# STM32F413xx register map
File version: 1.0
Registers are 32-bit, access not given, reset 0x0 unless marked. A register's access mark holds for its fields unless they carry their own. Offsets are from the block's base; [hi:lo] are bit positions; {n}, {i} and the like mark numbered series; 'fields as' and 'values as' point back to an identical list.

## SYSCFG
Base 0x40013800
0x00 MEMRMP
  [1:0] MEM_MODE
0x04 PMC
  [16] ADC1DC2
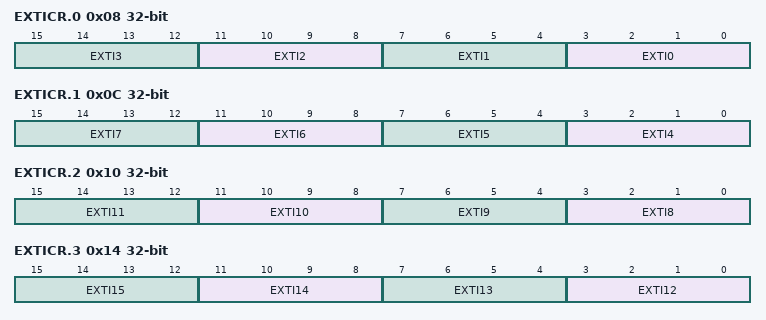
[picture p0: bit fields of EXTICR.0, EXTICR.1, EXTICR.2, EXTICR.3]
0x08 EXTICR.0
  [4n+3:4n] EXTI{n} (n=0..3)
0x0C EXTICR.1
  [4n-13:4n-16] EXTI{n} (n=4..7)
0x10 EXTICR.2
  [4n-29:4n-32] EXTI{n} (n=8..11)
0x14 EXTICR.3
  [4n-45:4n-48] EXTI{n} (n=12..15)
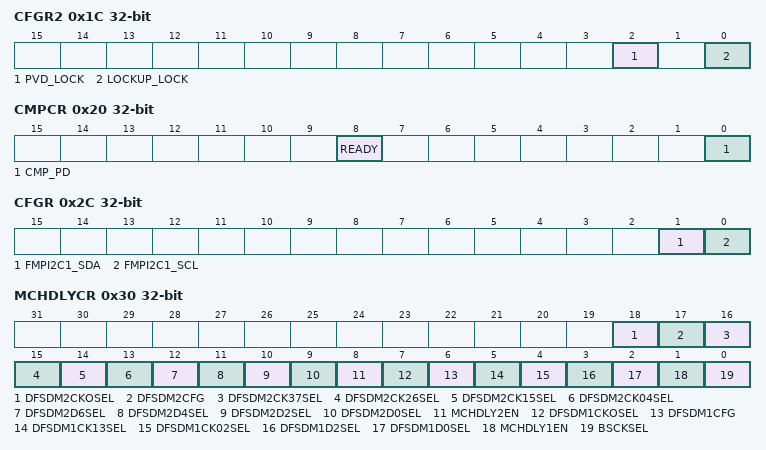
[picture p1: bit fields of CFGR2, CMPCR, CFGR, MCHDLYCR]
0x1C CFGR2
  [2] PVD_LOCK, [0] LOCKUP_LOCK
0x20 CMPCR
  [8] READY, [0] CMP_PD
0x2C CFGR
  [1] FMPI2C1_SDA, [0] FMPI2C1_SCL
0x30 MCHDLYCR
  [18] DFSDM2CKOSEL, [17] DFSDM2CFG, [16] DFSDM2CK37SEL, [15] DFSDM2CK26SEL, [14] DFSDM2CK15SEL, [13] DFSDM2CK04SEL, [12] DFSDM2D6SEL, [11] DFSDM2D4SEL, [10] DFSDM2D2SEL, [9] DFSDM2D0SEL, [8] MCHDLY2EN, [7] DFSDM1CKOSEL, [6] DFSDM1CFG, [5] DFSDM1CK13SEL, [4] DFSDM1CK02SEL, [3] DFSDM1D2SEL, [2] DFSDM1D0SEL, [1] MCHDLY1EN, [0] BSCKSEL

## EXTI
Base 0x40013C00
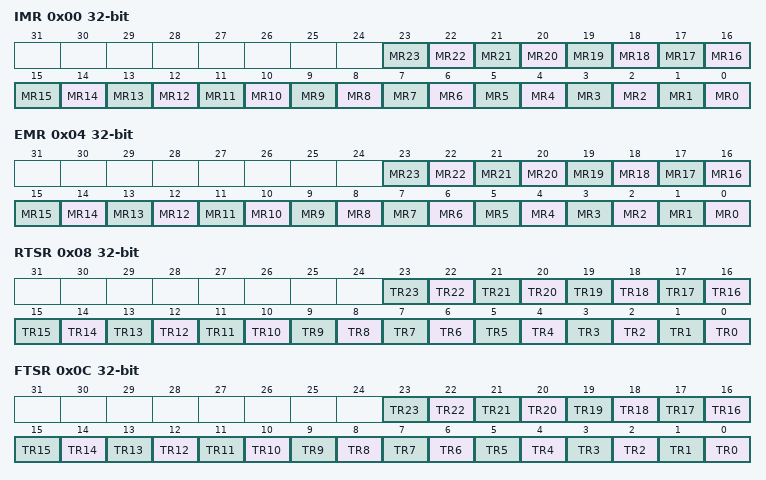
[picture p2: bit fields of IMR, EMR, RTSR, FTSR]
0x00 IMR
  [n] MR{n} (n=0..23)
0x04 EMR
  [n] MR{n} (n=0..23)
0x08 RTSR
  [n] TR{n} (n=0..23)
0x0C FTSR
  [n] TR{n} (n=0..23)
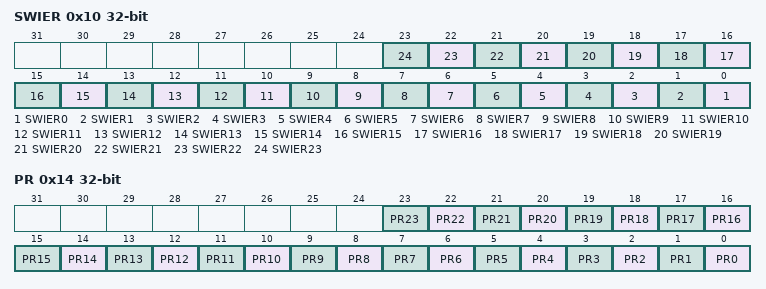
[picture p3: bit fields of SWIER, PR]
0x10 SWIER
  [n] SWIER{n} (n=0..23)
0x14 PR
  [n] PR{n} (n=0..23)

## SAI1
Base 0x40015800
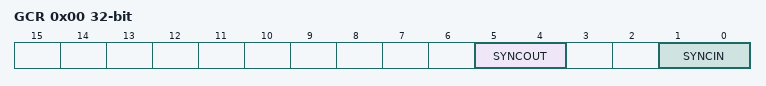
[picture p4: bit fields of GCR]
0x00 GCR
  [5:4] SYNCOUT, [1:0] SYNCIN
0x04 CR1A
0x08 CR2A
0x10 FRCRA
0x1C SLOTRA
0x24 CR1B
0x28 CR2B
0x2C IMRA
0x30 FRCRB
0x3C SLOTRB
0x40 SRA
0x4C IMRB
0x58 CLRFRA
0x60 SRB
0x74 DRA
0x78 CLRFRB
0x94 DRB

## DFSDM1
Base 0x40016000
Same registers: DFSDM2 0x40016400
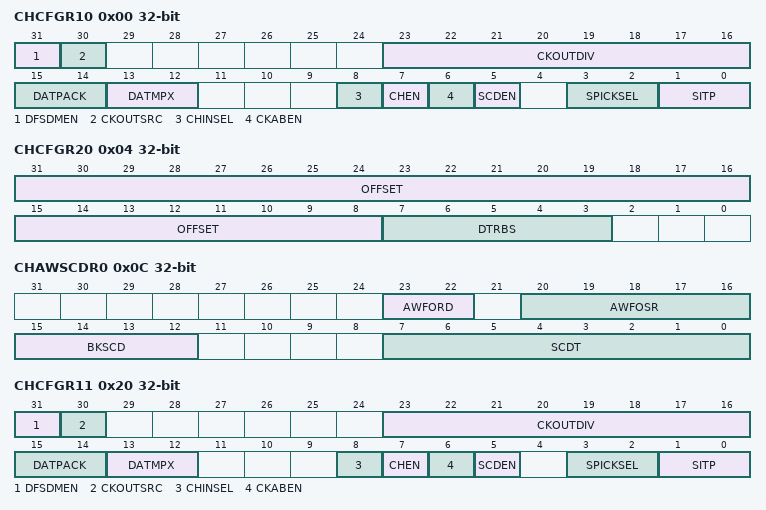
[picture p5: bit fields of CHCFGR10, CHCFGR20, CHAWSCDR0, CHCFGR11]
0x00 CHCFGR10
  [31] DFSDMEN, [30] CKOUTSRC, [23:16] CKOUTDIV, [15:14] DATPACK, [13:12] DATMPX, [8] CHINSEL, [7] CHEN, [6] CKABEN, [5] SCDEN, [3:2] SPICKSEL, [1:0] SITP
0x04 CHCFGR20
  [31:8] OFFSET, [7:3] DTRBS
0x0C CHAWSCDR0
  [23:22] AWFORD, [20:16] AWFOSR, [15:12] BKSCD, [7:0] SCDT
0x18 CHWDATAR0
0x20 CHCFGR11
  fields as CHCFGR10
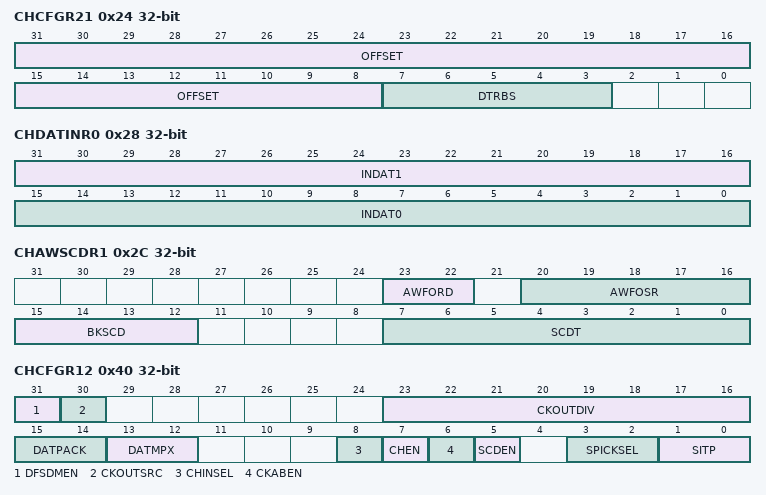
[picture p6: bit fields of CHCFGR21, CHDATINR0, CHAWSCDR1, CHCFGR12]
0x24 CHCFGR21
  [31:8] OFFSET, [7:3] DTRBS
0x28 CHDATINR0
  [31:16] INDAT1, [15:0] INDAT0
0x2C CHAWSCDR1
  [23:22] AWFORD, [20:16] AWFOSR, [15:12] BKSCD, [7:0] SCDT
0x38 CHWDATAR1
0x40 CHCFGR12
  fields as CHCFGR10
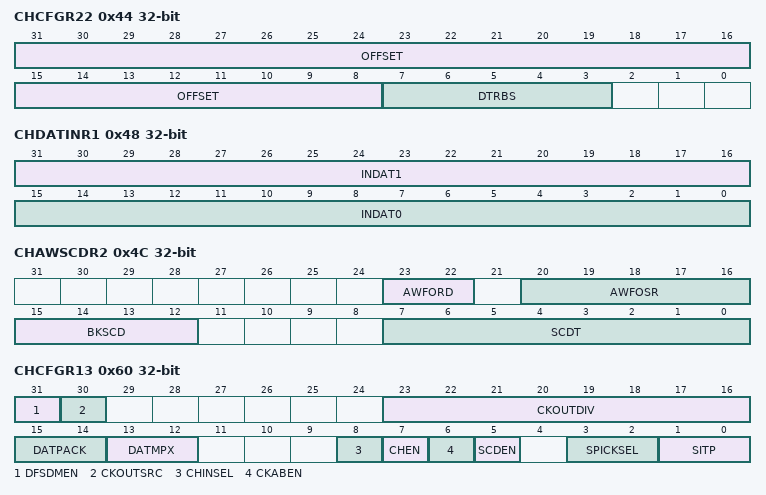
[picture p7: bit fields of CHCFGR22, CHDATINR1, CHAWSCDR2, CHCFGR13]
0x44 CHCFGR22
  [31:8] OFFSET, [7:3] DTRBS
0x48 CHDATINR1
  [31:16] INDAT1, [15:0] INDAT0
0x4C CHAWSCDR2
  [23:22] AWFORD, [20:16] AWFOSR, [15:12] BKSCD, [7:0] SCDT
0x58 CHWDATAR2
0x60 CHCFGR13
  fields as CHCFGR10
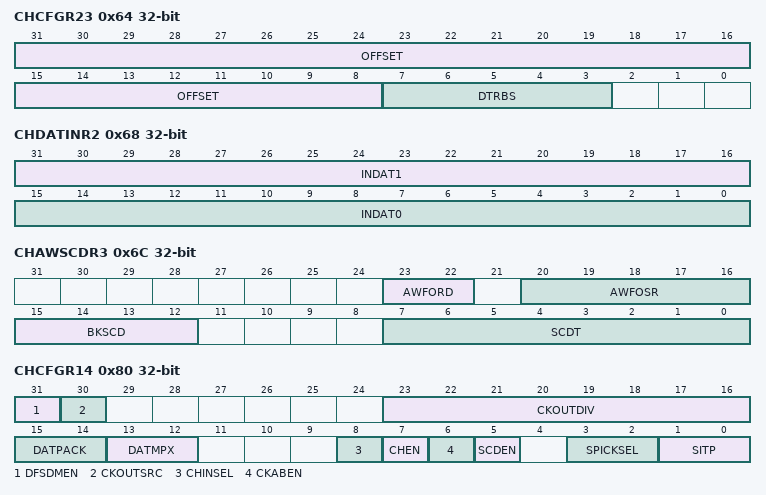
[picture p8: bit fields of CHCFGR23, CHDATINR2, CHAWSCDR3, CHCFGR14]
0x64 CHCFGR23
  [31:8] OFFSET, [7:3] DTRBS
0x68 CHDATINR2
  [31:16] INDAT1, [15:0] INDAT0
0x6C CHAWSCDR3
  [23:22] AWFORD, [20:16] AWFOSR, [15:12] BKSCD, [7:0] SCDT
0x78 CHWDATAR3
0x80 CHCFGR14
  fields as CHCFGR10
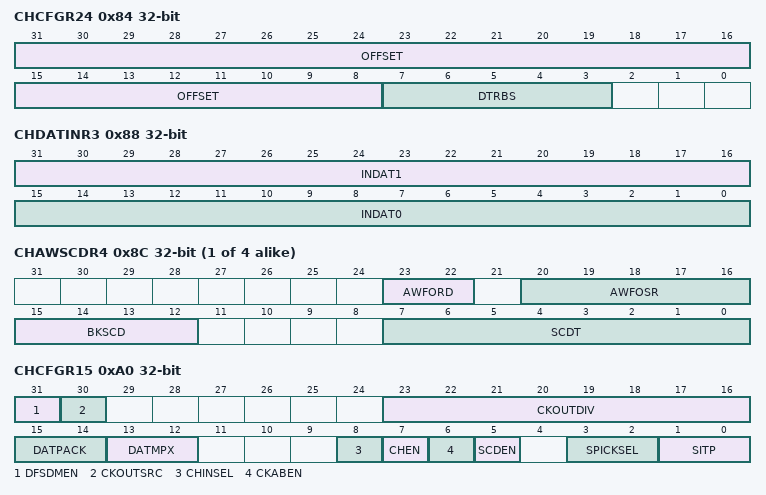
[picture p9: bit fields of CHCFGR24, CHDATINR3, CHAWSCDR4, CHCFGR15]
0x84 CHCFGR24
  [31:8] OFFSET, [7:3] DTRBS
0x88 CHDATINR3
  [31:16] INDAT1, [15:0] INDAT0
{0xC+0x20*i} CHAWSCDR{i} (i=4..7)
  [23:22] AWFORD, [20:16] AWFOSR, [15:12] BKSCD, [7:0] SCDT
{0x18+0x20*i} CHWDATAR{i} (i=4..7)
0xA0 CHCFGR15
  fields as CHCFGR10
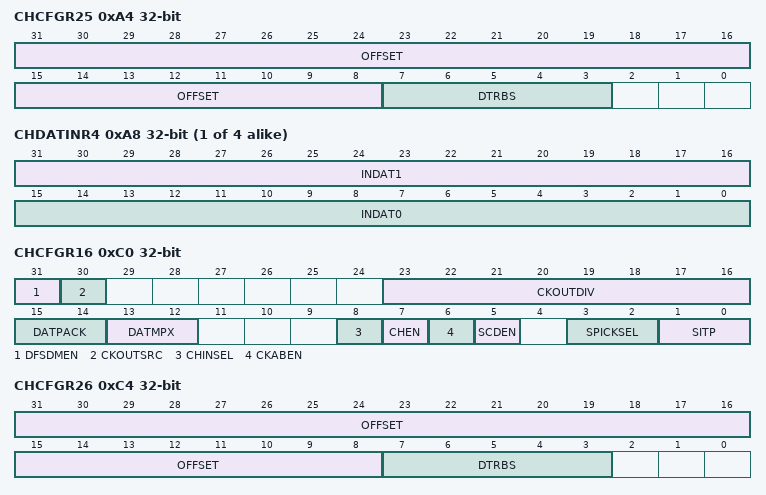
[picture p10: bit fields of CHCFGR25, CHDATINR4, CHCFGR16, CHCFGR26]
0xA4 CHCFGR25
  [31:8] OFFSET, [7:3] DTRBS
{0x28+0x20*i} CHDATINR{i} (i=4..7)
  [31:16] INDAT1, [15:0] INDAT0
0xC0 CHCFGR16
  fields as CHCFGR10
0xC4 CHCFGR26
  [31:8] OFFSET, [7:3] DTRBS
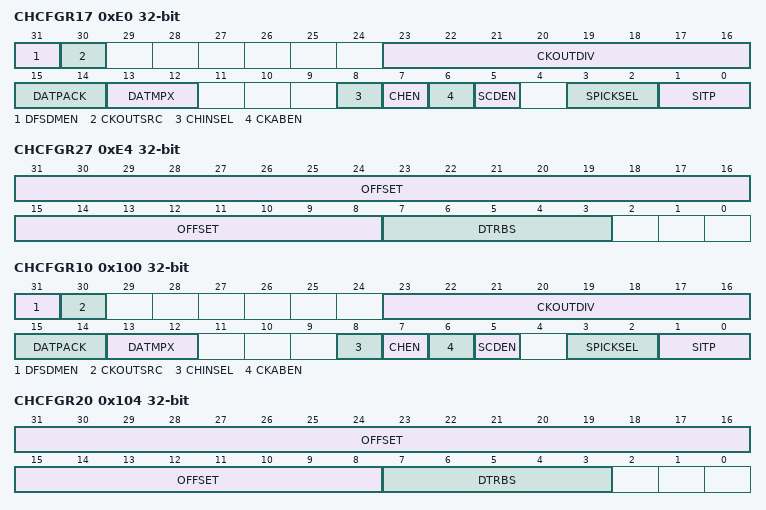
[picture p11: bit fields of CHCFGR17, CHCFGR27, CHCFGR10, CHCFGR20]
0xE0 CHCFGR17
  fields as CHCFGR10
0xE4 CHCFGR27
  [31:8] OFFSET, [7:3] DTRBS
0x100 CHCFGR10
  fields as CHCFGR10
0x104 CHCFGR20
  [31:8] OFFSET, [7:3] DTRBS
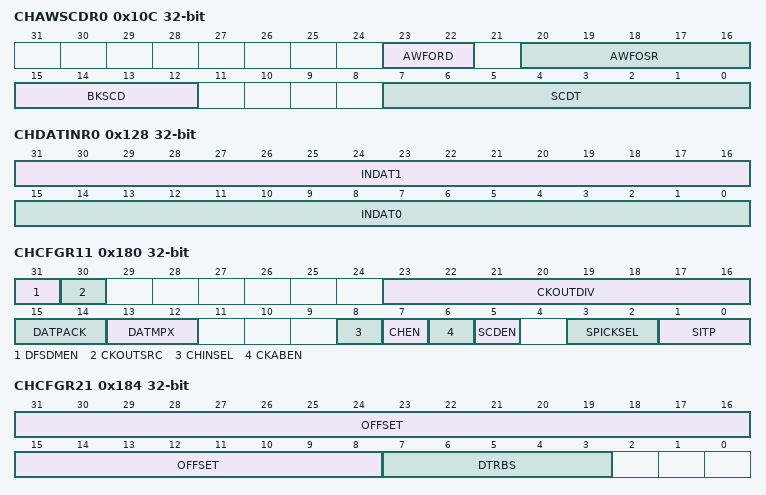
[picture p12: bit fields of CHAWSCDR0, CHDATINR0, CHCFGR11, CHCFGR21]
0x10C CHAWSCDR0
  [23:22] AWFORD, [20:16] AWFOSR, [15:12] BKSCD, [7:0] SCDT
0x118 CHWDATAR0
0x128 CHDATINR0
  [31:16] INDAT1, [15:0] INDAT0
0x180 CHCFGR11
  fields as CHCFGR10
0x184 CHCFGR21
  [31:8] OFFSET, [7:3] DTRBS
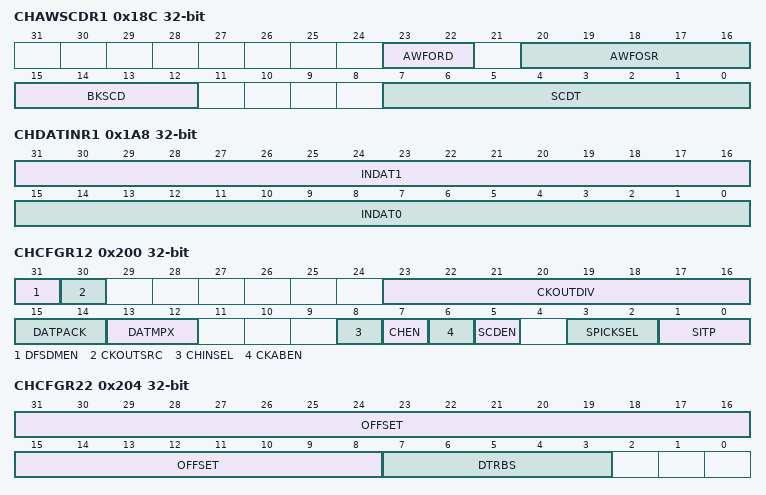
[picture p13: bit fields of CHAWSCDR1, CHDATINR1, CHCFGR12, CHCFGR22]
0x18C CHAWSCDR1
  [23:22] AWFORD, [20:16] AWFOSR, [15:12] BKSCD, [7:0] SCDT
0x198 CHWDATAR1
0x1A8 CHDATINR1
  [31:16] INDAT1, [15:0] INDAT0
0x200 CHCFGR12
  fields as CHCFGR10
0x204 CHCFGR22
  [31:8] OFFSET, [7:3] DTRBS
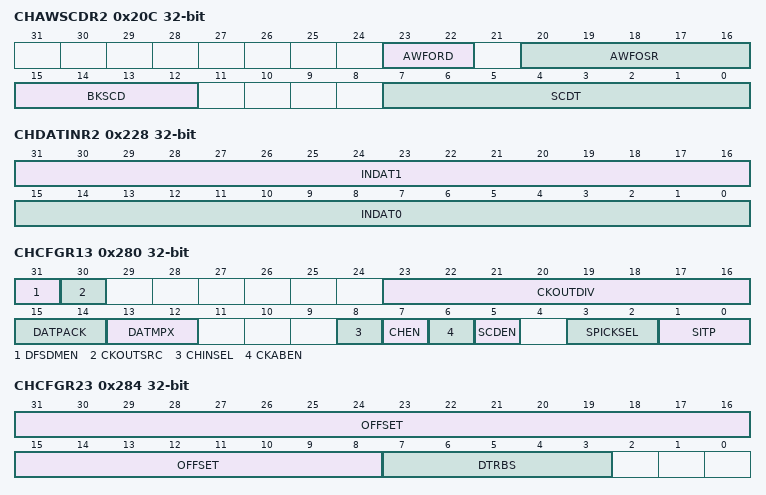
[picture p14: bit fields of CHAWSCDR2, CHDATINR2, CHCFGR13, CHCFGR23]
0x20C CHAWSCDR2
  [23:22] AWFORD, [20:16] AWFOSR, [15:12] BKSCD, [7:0] SCDT
0x218 CHWDATAR2
0x228 CHDATINR2
  [31:16] INDAT1, [15:0] INDAT0
0x280 CHCFGR13
  fields as CHCFGR10
0x284 CHCFGR23
  [31:8] OFFSET, [7:3] DTRBS
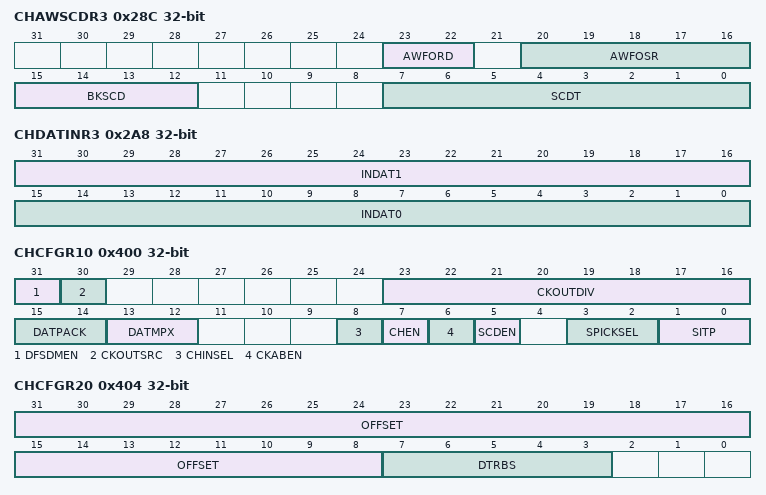
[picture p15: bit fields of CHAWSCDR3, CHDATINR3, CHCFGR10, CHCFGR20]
0x28C CHAWSCDR3
  [23:22] AWFORD, [20:16] AWFOSR, [15:12] BKSCD, [7:0] SCDT
0x298 CHWDATAR3
0x2A8 CHDATINR3
  [31:16] INDAT1, [15:0] INDAT0
0x400 CHCFGR10
  fields as CHCFGR10
0x404 CHCFGR20
  [31:8] OFFSET, [7:3] DTRBS
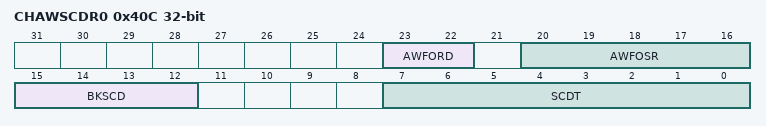
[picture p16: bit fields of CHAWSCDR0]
0x40C CHAWSCDR0
  [23:22] AWFORD, [20:16] AWFOSR, [15:12] BKSCD, [7:0] SCDT
0x418 CHWDATAR0
0x428 CHDATINR0
  [31:16] INDAT1, [15:0] INDAT0
